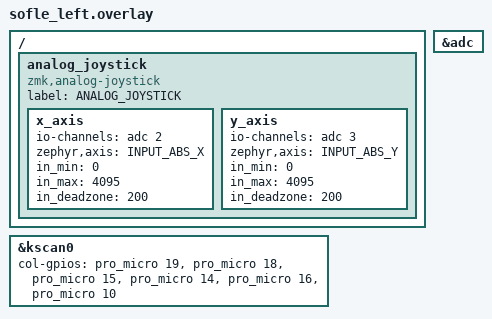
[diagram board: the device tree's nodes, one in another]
/*
 * Copyright (c) 2020 Ryan Cross
 *
 * SPDX-License-Identifier: MIT
 */

#include "sofle.dtsi"

&kscan0 {
    col-gpios
        = <&pro_micro 19 GPIO_ACTIVE_HIGH>
        , <&pro_micro 18 GPIO_ACTIVE_HIGH>
        , <&pro_micro 15 GPIO_ACTIVE_HIGH>
        , <&pro_micro 14 GPIO_ACTIVE_HIGH>
        , <&pro_micro 16 GPIO_ACTIVE_HIGH>
        , <&pro_micro 10 GPIO_ACTIVE_HIGH>
        ;
};

// 启用 ADC 硬件
&adc {
    status = "okay";
};

/ {
    // 定义一个名为 "analog_joystick" 的节点
    analog_joystick {
        // 关键：引用 ZMK 官方的摇杆驱动
        compatible = "zmk,analog-joystick"; 
        label = "ANALOG_JOYSTICK";

        // X 轴配置
        x_axis {
            io-channels = <&adc 2>; // 连接到 AIN0 (P0.02)
            zephyr,axis = <INPUT_ABS_X>; // 映射为 X 轴
            in_min = <0>;     // ADC 最小值
            in_max = <4095>;  // ADC 最大值
            in_deadzone = <200>; // 死区
        };

        // Y 轴配置 (同理)
        y_axis {
            io-channels = <&adc 3>; // 连接到 AIN1 (P0.03)
            zephyr,axis = <INPUT_ABS_Y>;
            in_min = <0>;
            in_max = <4095>;
            in_deadzone = <200>;
        };
    };
};


//  &left_encoder {
//     status = "okay";
// };



// &left_ex1_encoder {
//     status = "okay";
// };
